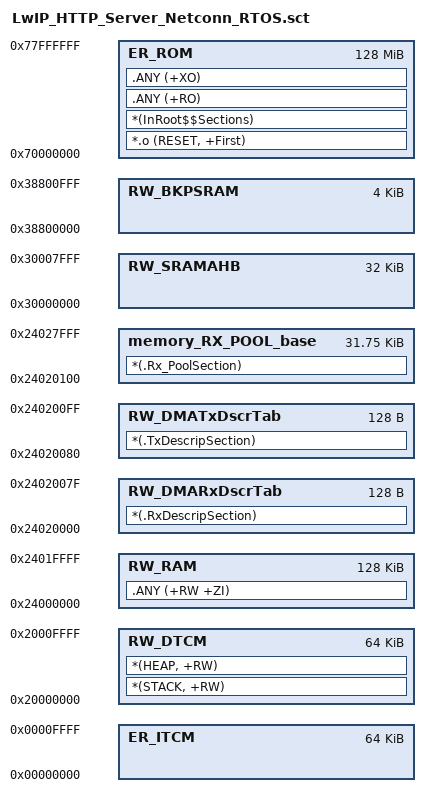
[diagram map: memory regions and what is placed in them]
; *************************************************************
; *** Scatter-Loading Description File generated by uVision ***
; *************************************************************
LOAD_FLASH 0x70000000 0x08000000  {    ; load region size_region
  ER_ROM 0x70000000 0x08000000  {  ; load address = execution address
   *.o (RESET, +First)
   *(InRoot$$Sections)
   .ANY (+RO)
   .ANY (+XO)
  }

  ER_ITCM 0x00000000 0x00010000  {  ;
  }

  RW_DTCM 0x20000000 0x00010000  {  ; RW data
   *(STACK, +RW)
   *(HEAP, +RW)
  }

  RW_SRAMAHB 0x30000000 0x8000  {
  }

  RW_BKPSRAM 0x38800000 0x1000  {
  }

  RW_RAM 0x24000000  0x00020000  {
   .ANY (+RW +ZI)
  }
  RW_DMARxDscrTab 0x24020000 0x80 {
  *(.RxDescripSection)
  }
  RW_DMATxDscrTab 0x24020080 0x80 {
  *(.TxDescripSection)
  }
  memory_RX_POOL_base 0x24020100 0x8000-0x100 {
  *(.Rx_PoolSection)
  }
}
